# npck3m7k register map
Registers are 8-bit, read-write, no defined reset value unless marked. A register's access mark holds for its fields unless they carry their own. Offsets are from the block's base; [hi:lo] are bit positions; {n}, {i} and the like mark numbered series.

## DSADC
Base 0x400D1100
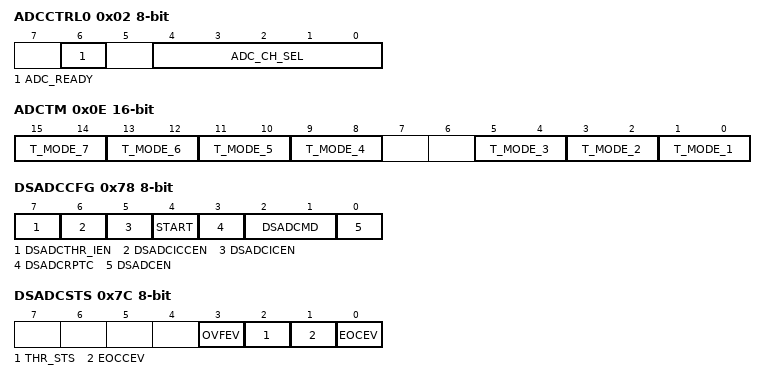
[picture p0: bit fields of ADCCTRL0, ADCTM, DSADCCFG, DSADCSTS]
0x02 ADCCTRL0
  [6] ADC_READY, [4:0] ADC_CH_SEL
0x04 ADCCTRL1
  [6:0] ADC_CLK_SEL
0x0E ADCTM 16-bit
  [2n+1:2n] T_MODE_{n} (n=4..7), [5:4] T_MODE_3, [3:2] T_MODE_2, [1:0] T_MODE_1
0x76 ANAD2 16-bit
  [8:0] ANAD2
0x78 DSADCCFG
  [7] DSADCTHR_IEN, [6] DSADCICCEN, [5] DSADCICEN, [4] START, [3] DSADCRPTC, [2:1] DSADCMD, [0] DSADCEN
0x7A DSADCCS
  [6:0] CC6-0
0x7C DSADCSTS
  [3] OVFEV, [2] THR_STS, [1] EOCCEV, [0] EOCEV
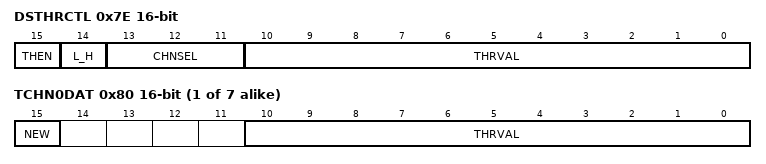
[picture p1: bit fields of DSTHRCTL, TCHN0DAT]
0x7E DSTHRCTL 16-bit
  [15] THEN, [14] L_H, [13:11] CHNSEL, [10:0] THRVAL
{0x80+2i} TCHN{i}DAT 16-bit (i=0..6)
  [15] NEW, [10:0] THRVAL

## PWM_A — Pluse-Width Modulator
Base 0x40080000
0x00 PRSCn 16-bit
0x02 CTRn 16-bit
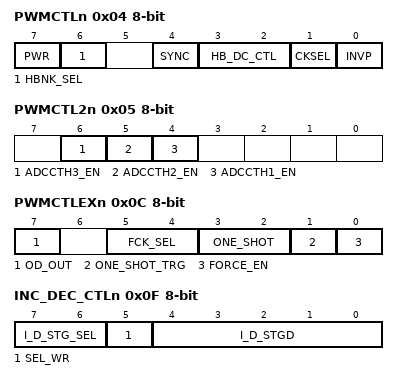
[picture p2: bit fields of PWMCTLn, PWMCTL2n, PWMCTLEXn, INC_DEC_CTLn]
0x04 PWMCTLn
  [7] PWR, [6] HBNK_SEL, [4] SYNC, [3:2] HB_DC_CTL, [1] CKSEL, [0] INVP
0x05 PWMCTL2n
  [6] ADCCTH3_EN, [5] ADCCTH2_EN, [4] ADCCTH1_EN
0x06 DCRn 16-bit
0x08 SEQLn 16-bit
0x0A SEQHn 16-bit
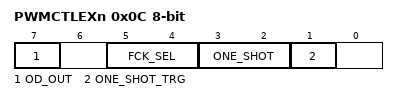
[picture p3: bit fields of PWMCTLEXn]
0x0C PWMCTLEXn
  [7] OD_OUT, [5:4] FCK_SEL, [3:2] ONE_SHOT, [1] ONE_SHOT_TRG, [0] FORCE_EN
0x0E PWMn_VER
0x0F INC_DEC_CTLn
  [7:6] I_D_STG_SEL, [5] SEL_WR, [4:0] I_D_STGD

## PWM_B — Pluse-Width Modulator
Base 0x40082000
Same registers: PWM_C 0x40084000, PWM_D 0x40086000, PWM_E 0x40088000, PWM_F 0x4008A000, PWM_G 0x4008C000, PWM_H 0x4008E000, PWM_I 0x40090000, PWM_J 0x40092000, PWM_K 0x40094000, PWM_L 0x40096000, PWM_M 0x40098000
Registers as PWM_A; these are added or differ:
0x0C PWMCTLEXn
  [7] OD_OUT, [5:4] FCK_SEL, [3:2] ONE_SHOT, [1] ONE_SHOT_TRG

## MIWU-1 — MULTI-INPUT WAKE-UP
Base 0x400BB000
Same registers: MIWU-1 0x400BF000, MIWU-1 0x400BF000
0x00 WKEDG1
0x01 WKAEDG1
0x0A WKPND1
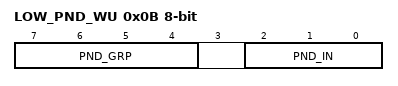
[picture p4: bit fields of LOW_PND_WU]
0x0B LOW_PND_WU
  [7:4] PND_GRP, [2:0] PND_IN
0x0C WKPCL1
0x0F MIWU_VER
0x1E WKEN1
0x1F WKINEN1
0x70 WKMOD1
0x70 WKMOD1

## MIWU-2 — MULTI-INPUT WAKE-UP
Base 0x400BB000
Same registers: MIWU-2 0x400BD000, MIWU-2 0x400BD000, MIWU-2 0x400BD000, MIWU-2 0x400BD000, MIWU-2 0x400BF000, MIWU-2 0x400BF000
0x02 WKEDG2
0x03 WKAEDG2
0x0E WKPND2
0x10 WKPCL2
0x20 WKEN2
0x21 WKINEN2
0x71 WKMOD2

## MIWU-3 — MULTI-INPUT WAKE-UP
Base 0x400BB000
Same registers: MIWU-3 0x400BD000, MIWU-3 0x400BD000, MIWU-3 0x400BD000, MIWU-3 0x400BD000, MIWU-3 0x400BF000, MIWU-3 0x400BF000
0x04 WKEDG3
0x05 WKAEDG3
0x12 WKPND3
0x14 WKPCL3
0x22 WKEN3
0x23 WKINEN3
0x72 WKMOD3

## MIWU-4 — MULTI-INPUT WAKE-UP
Base 0x400BB000
Same registers: MIWU-4 0x400BD000, MIWU-4 0x400BD000, MIWU-4 0x400BD000, MIWU-4 0x400BD000, MIWU-4 0x400BF000, MIWU-4 0x400BF000
0x06 WKEDG4
0x07 WKAEDG4
0x16 WKPND4
0x18 WKPCL4
0x24 WKEN4
0x25 WKINEN4
0x73 WKMOD4

## MIWU-5 — MULTI-INPUT WAKE-UP
Base 0x400BB000
Same registers: MIWU-5 0x400BD000, MIWU-5 0x400BD000, MIWU-5 0x400BD000, MIWU-5 0x400BD000, MIWU-5 0x400BF000, MIWU-5 0x400BF000
0x08 WKEDG5
0x09 WKAEDG5
0x1A WKPND5
0x1C WKPCL5
0x26 WKEN5
0x27 WKINEN5
0x74 WKMOD5

## MIWU-6 — MULTI-INPUT WAKE-UP
Base 0x400BB000
Same registers: MIWU-6 0x400BD000, MIWU-6 0x400BD000, MIWU-6 0x400BD000, MIWU-6 0x400BD000, MIWU-6 0x400BF000, MIWU-6 0x400BF000
0x28 WKEDG6
0x29 WKAEDG6
0x2E WKPND6
0x30 WKPCL6
0x3A WKEN6
0x3B WKINEN6
0x75 WKMOD6

## MIWU-7 — MULTI-INPUT WAKE-UP
Base 0x400BB000
Same registers: MIWU-7 0x400BD000, MIWU-7 0x400BD000, MIWU-7 0x400BD000, MIWU-7 0x400BD000, MIWU-7 0x400BF000, MIWU-7 0x400BF000
0x2A WKEDG7
0x2B WKAEDG7
0x32 WKPND7
0x34 WKPCL7
0x3C WKEN7
0x3D WKINEN7
0x76 WKMOD7

## MIWU-8 — MULTI-INPUT WAKE-UP
Base 0x400BB000
Same registers: MIWU-8 0x400BD000, MIWU-8 0x400BD000, MIWU-8 0x400BD000, MIWU-8 0x400BD000, MIWU-8 0x400BF000, MIWU-8 0x400BF000
0x2C WKEDG8
0x2D WKAEDG8
0x36 WKPND8
0x38 WKPCL8
0x3E WKEN8
0x3F WKINEN8
0x77 WKMOD8
